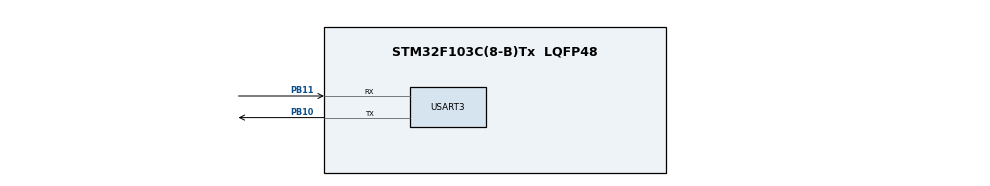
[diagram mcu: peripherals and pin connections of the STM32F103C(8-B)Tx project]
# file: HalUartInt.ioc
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Mcu.Family=STM32F1
Mcu.Name=STM32F103C(8-B)Tx
Mcu.Package=LQFP48
NVIC.PriorityGroup=NVIC_PRIORITYGROUP_4
NVIC.USART3_IRQn=true\:0\:0\:false\:false\:true\:true\:true
PA13.Mode=Serial_Wire
PA13.Signal=SYS_JTMS-SWDIO
PA14.Mode=Serial_Wire
PA14.Signal=SYS_JTCK-SWCLK
PB10.Mode=Asynchronous
PB10.Signal=USART3_TX
PB11.Mode=Asynchronous
PB11.Signal=USART3_RX
ProjectManager.HeapSize=0x200
ProjectManager.StackSize=0x400
ProjectManager.TargetToolchain=Makefile
RCC.APB1Freq_Value=8000000
RCC.APB2Freq_Value=8000000
USART3.VirtualMode=VM_ASYNC
board=custom

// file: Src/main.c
/* USER CODE BEGIN Header */
/**
  ******************************************************************************
  * @file           : main.c
  * @brief          : Main program body
  ******************************************************************************
  * @attention
  *
  * <h2><center>&copy; Copyright (c) 2020 STMicroelectronics.
  * All rights reserved.</center></h2>
  *
  * This software component is licensed by ST under BSD 3-Clause license,
  * the "License"; You may not use this file except in compliance with the
  * License. You may obtain a copy of the License at:
  *                        opensource.org/licenses/BSD-3-Clause
  *
  ******************************************************************************
  */
/* USER CODE END Header */

#include "main.h"

UART_HandleTypeDef huart3;

void SystemClock_Config(void);
static void MX_GPIO_Init(void);
static void MX_USART3_UART_Init(void);

/* USER CODE BEGIN 0 */
uint8_t miniBuffer;
/* USER CODE END 0 */

int main(void)
{

  /* MCU Configuration--------------------------------------------------------*/

  /* Reset of all peripherals, Initializes the Flash interface and the Systick. */
  HAL_Init();

  /* Configure the system clock */
  SystemClock_Config();

  /* Initialize all configured peripherals */
  MX_GPIO_Init();
  MX_USART3_UART_Init();
  /* USER CODE BEGIN 2 */
  /*
    Ok long story:
    HAL_UART_Receive_IT sets up an interrupt operation for n bits.
    There seems to be a bug when if there is a tx running when the rx tries to run they
    will deadlock or fail.
  */
  ///HAL_UART_Receive_IT(&huart3, &miniBuffer, 1);

  //This is to enable the interrupt whithout messing with HAL_UART_tx/rx_IT functions
  __HAL_UART_ENABLE_IT(&huart3, UART_IT_RXNE);

  /* USER CODE END 2 */

   /* Infinite loop */
  while (1)
  {

  }
}

void SystemClock_Config(void)
{
  RCC_OscInitTypeDef RCC_OscInitStruct = {0};
  RCC_ClkInitTypeDef RCC_ClkInitStruct = {0};

  /** Initializes the CPU, AHB and APB busses clocks
  */
  RCC_OscInitStruct.OscillatorType = RCC_OSCILLATORTYPE_HSI;
  RCC_OscInitStruct.HSIState = RCC_HSI_ON;
  RCC_OscInitStruct.HSICalibrationValue = RCC_HSICALIBRATION_DEFAULT;
  RCC_OscInitStruct.PLL.PLLState = RCC_PLL_NONE;
  if (HAL_RCC_OscConfig(&RCC_OscInitStruct) != HAL_OK)
  {
    Error_Handler();
  }
  /** Initializes the CPU, AHB and APB busses clocks
  */
  RCC_ClkInitStruct.ClockType = RCC_CLOCKTYPE_HCLK|RCC_CLOCKTYPE_SYSCLK
                              |RCC_CLOCKTYPE_PCLK1|RCC_CLOCKTYPE_PCLK2;
  RCC_ClkInitStruct.SYSCLKSource = RCC_SYSCLKSOURCE_HSI;
  RCC_ClkInitStruct.AHBCLKDivider = RCC_SYSCLK_DIV1;
  RCC_ClkInitStruct.APB1CLKDivider = RCC_HCLK_DIV1;
  RCC_ClkInitStruct.APB2CLKDivider = RCC_HCLK_DIV1;

  if (HAL_RCC_ClockConfig(&RCC_ClkInitStruct, FLASH_LATENCY_0) != HAL_OK)
  {
    Error_Handler();
  }
}

static void MX_USART3_UART_Init(void)
{

  huart3.Instance = USART3;
  huart3.Init.BaudRate = 115200;
  huart3.Init.WordLength = UART_WORDLENGTH_8B;
  huart3.Init.StopBits = UART_STOPBITS_1;
  huart3.Init.Parity = UART_PARITY_NONE;
  huart3.Init.Mode = UART_MODE_TX_RX;
  huart3.Init.HwFlowCtl = UART_HWCONTROL_NONE;
  huart3.Init.OverSampling = UART_OVERSAMPLING_16;
  if (HAL_UART_Init(&huart3) != HAL_OK)
  {
    Error_Handler();
  }
  /* USER CODE BEGIN USART3_Init 2 */
  //For whatever reason this was not set by CubeMX.
  // NEEDS! to be added or interrupts wont work
  HAL_NVIC_SetPriority(USART3_IRQn, 0, 0);
  HAL_NVIC_EnableIRQ(USART3_IRQn);
  /* USER CODE END USART3_Init 2 */

}

static void MX_GPIO_Init(void)
{

  /* GPIO Ports Clock Enable */
  __HAL_RCC_GPIOB_CLK_ENABLE();
  __HAL_RCC_GPIOA_CLK_ENABLE();

}

/* USER CODE BEGIN 4 */

/* This callback is called by the HAL_UART_IRQHandler when the given number of bytes are received */
/*That description is actually very succint
The normal HAL process is to set the HAL_UART_Receive_IT
Once all data has been received this functions is run however it is not continuous execution
Hence you need to issue HAL_UART_Receive_IT again to make it work!
That is kinda hacky and there are reported bugs with it where it won't work if a tx operation
is running in parallel
But could be usefull if frequency of RX >>> TX or to receive 4 bytes at once
*/
void HAL_UART_RxCpltCallback(UART_HandleTypeDef *huart)
{
  if (huart->Instance == USART3)
  {
    /* Transmit one byte with 100 ms timeout */
   HAL_UART_Transmit(&huart3, &miniBuffer, 1, 100);

    /* Receive one byte in interrupt mode */
   HAL_UART_Receive_IT(&huart3, &miniBuffer, 1);
  }
}

/*This is the actual function that gets called when the intettupt is triggered
Normall the //HAL_UART_IRQHandler is run and when the full read is done
HAL_UART_RxCpltCallback is called.
Here I used raw acces to the uart to do read and write.
Using HAL_UART_Transmit failed as for whatever readon it did not cleared
the data from the DR register hence getting stuck at interruption
I think
*/

void USART3_IRQHandler(void)
{
  /* USER CODE BEGIN USART3_IRQn 0 */

  /* USER CODE END USART3_IRQn 0 */
  //HAL_UART_IRQHandler(&huart3);
  /* USER CODE BEGIN USART3_IRQn 1 */
  //Is RX register not empty?
  if(USART3->SR & USART_SR_RXNE)
  {
    //Could also use huart->instance->SR/DR etc
    char tmp = USART3->DR;
    USART3->DR = tmp;
    //HAL_UART_Transmit(&huart3, &miniBuffer, 1, 100);
  }
  /* USER CODE END USART3_IRQn 1 */
}

/* USER CODE END 4 */

void Error_Handler(void)
{
}

/************************ (C) COPYRIGHT STMicroelectronics *****END OF FILE****/
